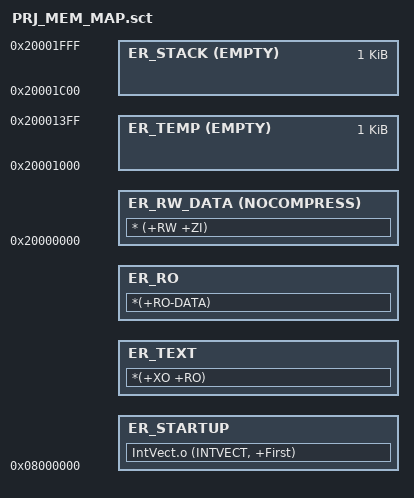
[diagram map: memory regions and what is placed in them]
; *************************************************************
; *** Scatter-Loading Description File generated by uVision ***
; *************************************************************

LR_MEM_MAP 0x08000000 0x00020000  
{
	ER_STARTUP +0  ALIGN 4 
	{
		IntVect.o (INTVECT, +First) ;.INTVECT section (Entry point defined by the linker cmd --entry SysStartup_Init)
	}

	ER_TEXT +0  ALIGN 4  ; +0 means current position 
	{
		*(+XO +RO) ;.text section  
	}
	
	ER_RO +0  ALIGN 4  ; +0 means current position 
	{
		*(+RO-DATA) ;.constdata(.rodata) section
	}	

	ER_RW_DATA 0x20000000 NOCOMPRESS  ALIGN 4  
	{
		* (+RW +ZI) ; .data and .bss sections
	}
	
	ER_TEMP 0x20001000 EMPTY 0x400
	{                                  
	}	
	
	ER_STACK 0x20002000 EMPTY -0x400   ; region ends at 0x20002000 because of the
	{                                  ; negative length. The start of the region
	}                                  ; is defined in symbol: Image$$STACK$$ZI$$Limit
}


